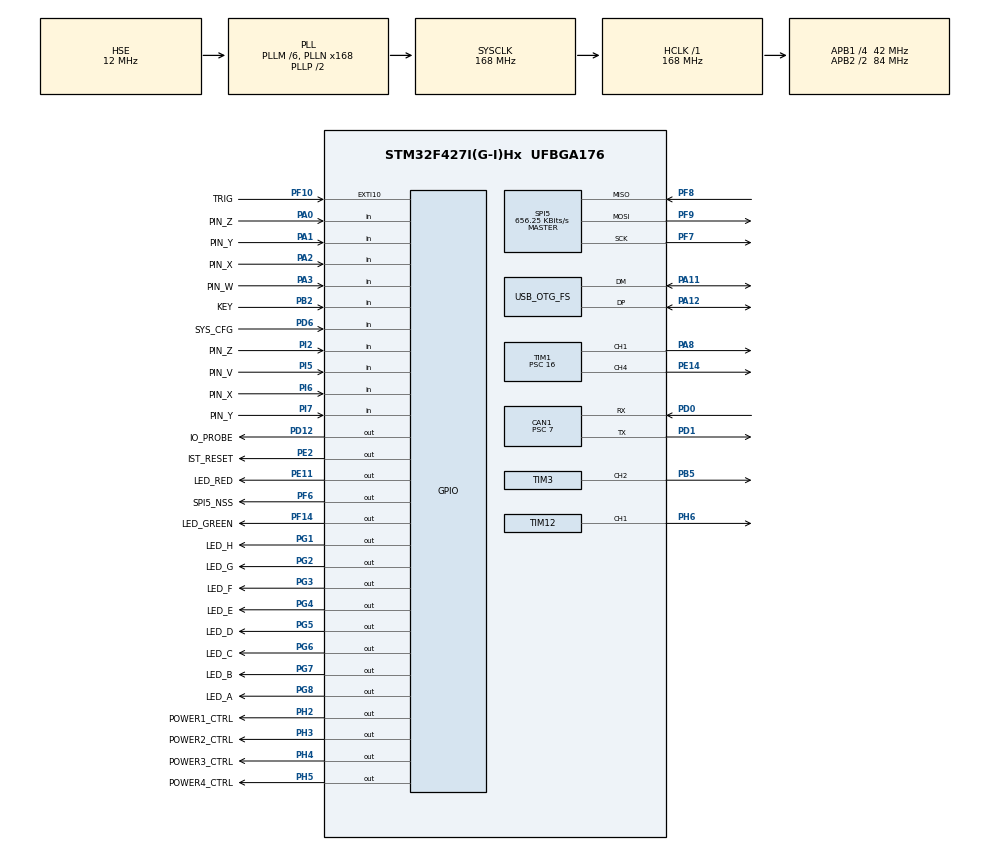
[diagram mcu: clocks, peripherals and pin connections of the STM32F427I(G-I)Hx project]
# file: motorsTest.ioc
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CAN1.BS1=CAN_BS1_2TQ
CAN1.BS2=CAN_BS2_3TQ
CAN1.CalculateBaudRate=999999
CAN1.CalculateTimeBit=1000
CAN1.CalculateTimeQuantum=166.66666666666669
CAN1.Prescaler=7
CAN1.TXFP=ENABLE
FREERTOS.INCLUDE_vTaskDelayUntil=1
FREERTOS.MEMORY_ALLOCATION=0
FREERTOS.Tasks01=defaultTask,0,128,StartDefaultTask,Default,NULL,Dynamic,NULL,NULL
FREERTOS.configCHECK_FOR_STACK_OVERFLOW=2
FREERTOS.configUSE_MALLOC_FAILED_HOOK=1
FREERTOS.configUSE_NEWLIB_REENTRANT=1
Mcu.Family=STM32F4
Mcu.Name=STM32F427I(G-I)Hx
Mcu.Package=UFBGA176
NVIC.CAN1_RX0_IRQn=true\:5\:0\:false\:false\:true\:true\:true\:true\:true
NVIC.CAN1_TX_IRQn=true\:5\:0\:false\:false\:true\:true\:true\:true\:true
NVIC.OTG_FS_IRQn=true\:5\:0\:false\:false\:true\:true\:false\:true\:true
NVIC.PriorityGroup=NVIC_PRIORITYGROUP_4
NVIC.TIM2_IRQn=true\:5\:0\:false\:false\:true\:true\:true\:true\:true
NVIC.TIM5_IRQn=true\:15\:0\:false\:false\:true\:false\:false\:true\:true
NVIC.TimeBase=TIM5_IRQn
NVIC.TimeBaseIP=TIM5
PA0/WKUP.GPIO_Label=PIN_Z
PA0/WKUP.Signal=GPIO_Input
PA1.GPIO_Label=PIN_Y
PA1.Signal=GPIO_Input
PA11.Mode=Device_Only
PA11.Signal=USB_OTG_FS_DM
PA12.Mode=Device_Only
PA12.Signal=USB_OTG_FS_DP
PA13.Mode=Serial_Wire
PA13.Signal=SYS_JTMS-SWDIO
PA14.Mode=Serial_Wire
PA14.Signal=SYS_JTCK-SWCLK
PA2.GPIO_Label=PIN_X
PA2.Signal=GPIO_Input
PA3.GPIO_Label=PIN_W
PA3.Signal=GPIO_Input
PA8.Signal=S_TIM1_CH1
PB13.Signal=CAN2_TX
PB2/BOOT1.GPIO_Label=KEY
PB2/BOOT1.Signal=GPIO_Input
PB5.Signal=S_TIM3_CH2
PD0.Mode=CAN_Activate
PD0.Signal=CAN1_RX
PD1.Mode=CAN_Activate
PD1.Signal=CAN1_TX
PD12.GPIO_Label=IO_PROBE
PD12.Signal=GPIO_Output
PD6.GPIO_Label=SYS_CFG
PD6.Signal=GPIO_Input
PD8.GPIO_PuPd=GPIO_PULLUP
PD8.Signal=USART3_TX
PD9.GPIO_PuPd=GPIO_PULLUP
PD9.Signal=USART3_RX
PE11.GPIO_Label=LED_RED
PE11.Signal=GPIO_Output
PE14.Signal=S_TIM1_CH4
PE2.GPIO_Label=IST_RESET
PE2.Signal=GPIO_Output
PF10.GPIO_Label=TRIG
PF10.GPIO_PuPd=GPIO_PULLUP
PF10.Signal=GPXTI10
PF14.GPIO_Label=LED_GREEN
PF14.Signal=GPIO_Output
PF6.GPIO_Label=SPI5_NSS
PF6.Signal=GPIO_Output
PF7.Mode=Full_Duplex_Master
PF7.Signal=SPI5_SCK
PF8.Mode=Full_Duplex_Master
PF8.Signal=SPI5_MISO
PF9.Mode=Full_Duplex_Master
PF9.Signal=SPI5_MOSI
PG1.GPIO_Label=LED_H
PG1.Signal=GPIO_Output
PG2.GPIO_Label=LED_G
PG2.Signal=GPIO_Output
PG3.GPIO_Label=LED_F
PG3.Signal=GPIO_Output
PG4.GPIO_Label=LED_E
PG4.Signal=GPIO_Output
PG5.GPIO_Label=LED_D
PG5.Signal=GPIO_Output
PG6.GPIO_Label=LED_C
PG6.Signal=GPIO_Output
PG7.GPIO_Label=LED_B
PG7.Signal=GPIO_Output
PG8.GPIO_Label=LED_A
PG8.Signal=GPIO_Output
PH0/OSC_IN.Mode=HSE-External-Oscillator
PH0/OSC_IN.Signal=RCC_OSC_IN
PH1/OSC_OUT.Mode=HSE-External-Oscillator
PH1/OSC_OUT.Signal=RCC_OSC_OUT
PH2.GPIO_Label=POWER1_CTRL
PH2.Signal=GPIO_Output
PH3.GPIO_Label=POWER2_CTRL
PH3.Signal=GPIO_Output
PH4.GPIO_Label=POWER3_CTRL
PH4.Signal=GPIO_Output
PH5.GPIO_Label=POWER4_CTRL
PH5.Signal=GPIO_Output
PH6.Signal=S_TIM12_CH1
PI2.GPIO_Label=PIN_Z
PI2.Signal=GPIO_Input
PI5.GPIO_Label=PIN_V
PI5.Signal=GPIO_Input
PI6.GPIO_Label=PIN_X
PI6.Signal=GPIO_Input
PI7.GPIO_Label=PIN_Y
PI7.Signal=GPIO_Input
ProjectManager.HeapSize=0x200
ProjectManager.StackSize=0x400
ProjectManager.TargetToolchain=STM32CubeIDE
RCC.48MHZClocksFreq_Value=48000000
RCC.AHBFreq_Value=168000000
RCC.APB1CLKDivider=RCC_HCLK_DIV4
RCC.APB1Freq_Value=42000000
RCC.APB1TimFreq_Value=84000000
RCC.APB2CLKDivider=RCC_HCLK_DIV2
RCC.APB2Freq_Value=84000000
RCC.APB2TimFreq_Value=168000000
RCC.CortexFreq_Value=168000000
RCC.HCLKFreq_Value=168000000
RCC.HSE_VALUE=12000000
RCC.HSI_VALUE=16000000
RCC.LSE_VALUE=32768
RCC.PLLM=6
RCC.PLLN=168
RCC.PLLQ=7
RCC.SYSCLKFreq_VALUE=168000000
RCC.SYSCLKSource=RCC_SYSCLKSOURCE_PLLCLK
RCC.VCOOutputFreq_Value=336000000
SH.S_TIM12_CH1.0=TIM12_CH1,PWM Generation1 CH1
SH.S_TIM1_CH1.0=TIM1_CH1,PWM Generation1 CH1
SH.S_TIM1_CH4.0=TIM1_CH4,PWM Generation4 CH4
SH.S_TIM3_CH2.0=TIM3_CH2,PWM Generation2 CH2
SPI5.BaudRatePrescaler=SPI_BAUDRATEPRESCALER_128
SPI5.CalculateBaudRate=656.25 KBits/s
SPI5.Direction=SPI_DIRECTION_2LINES
SPI5.Mode=SPI_MODE_MASTER
SPI5.VirtualType=VM_MASTER
TIM1.Channel-PWM\ Generation1\ CH1=TIM_CHANNEL_1
TIM1.Channel-PWM\ Generation4\ CH4=TIM_CHANNEL_4
TIM1.Period=20000-1
TIM1.Prescaler=16
TIM1.Pulse-PWM\ Generation1\ CH1=1000
TIM1.Pulse-PWM\ Generation4\ CH4=1000
TIM12.Channel-PWM\ Generation1\ CH1=TIM_CHANNEL_1
TIM12.Period=20000-1
TIM12.Prescaler=83
TIM2.Period=1000-1
TIM2.Prescaler=83
TIM3.Channel-PWM\ Generation2\ CH2=TIM_CHANNEL_2
TIM3.Period=2000-1
TIM3.Prescaler=83
USB_DEVICE.CLASS_NAME_FS=CDC
USB_DEVICE.VirtualMode-CDC_FS=Cdc
USB_DEVICE.VirtualModeFS=Cdc_FS
USB_OTG_FS.VirtualMode=Device_Only
VP_FREERTOS_VS_CMSIS_V1.Mode=CMSIS_V1
VP_SYS_VS_tim5.Mode=TIM5
VP_TIM2_VS_ClockSourceINT.Mode=Internal
VP_USB_DEVICE_VS_USB_DEVICE_CDC_FS.Mode=CDC_FS
board=custom

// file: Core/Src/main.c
/* USER CODE BEGIN Header */
/**
 ******************************************************************************
 * @file           : main.c
 * @brief          : Main program body
 ******************************************************************************
 * @attention
 *
 * Copyright (c) 2024 STMicroelectronics.
 * All rights reserved.
 *
 * This software is licensed under terms that can be found in the LICENSE file
 * in the root directory of this software component.
 * If no LICENSE file comes with this software, it is provided AS-IS.
 *
 ******************************************************************************
 */
/* USER CODE END Header */
#include "main.h"
#include "can.h"
#include "cmsis_os.h"
#include "gpio.h"
#include "spi.h"
#include "tim.h"
#include "usb_device.h"

/* USER CODE BEGIN Includes */
#include "init.h"
/* USER CODE END Includes */

void SystemClock_Config(void);
void MX_FREERTOS_Init(void);

int main(void) {

  /* MCU Configuration--------------------------------------------------------*/

  /* Reset of all peripherals, Initializes the Flash interface and the Systick.
   */
  HAL_Init();

  /* Configure the system clock */
  SystemClock_Config();

  /* Initialize all configured peripherals */
  MX_GPIO_Init();
  MX_SPI5_Init();
  MX_CAN1_Init();
  MX_TIM1_Init();
  MX_TIM2_Init();
  MX_TIM3_Init();
  MX_TIM12_Init();
  /* USER CODE BEGIN 2 */
  hw_init();
  init_task();
  /* USER CODE END 2 */

  /* Call init function for freertos objects (in freertos.c) */
  MX_FREERTOS_Init();

  /* Start scheduler */
  osKernelStart();

  /* We should never get here as control is now taken by the scheduler */
  /* Infinite loop */
  while (1) {

  }
}

void SystemClock_Config(void) {
  RCC_OscInitTypeDef RCC_OscInitStruct = {0};
  RCC_ClkInitTypeDef RCC_ClkInitStruct = {0};

  /** Configure the main internal regulator output voltage
   */
  __HAL_RCC_PWR_CLK_ENABLE();
  __HAL_PWR_VOLTAGESCALING_CONFIG(PWR_REGULATOR_VOLTAGE_SCALE1);

  /** Initializes the RCC Oscillators according to the specified parameters
   * in the RCC_OscInitTypeDef structure.
   */
  RCC_OscInitStruct.OscillatorType = RCC_OSCILLATORTYPE_HSE;
  RCC_OscInitStruct.HSEState = RCC_HSE_ON;
  RCC_OscInitStruct.PLL.PLLState = RCC_PLL_ON;
  RCC_OscInitStruct.PLL.PLLSource = RCC_PLLSOURCE_HSE;
  RCC_OscInitStruct.PLL.PLLM = 6;
  RCC_OscInitStruct.PLL.PLLN = 168;
  RCC_OscInitStruct.PLL.PLLP = RCC_PLLP_DIV2;
  RCC_OscInitStruct.PLL.PLLQ = 7;
  if (HAL_RCC_OscConfig(&RCC_OscInitStruct) != HAL_OK) {
    Error_Handler();
  }

  /** Initializes the CPU, AHB and APB buses clocks
   */
  RCC_ClkInitStruct.ClockType = RCC_CLOCKTYPE_HCLK | RCC_CLOCKTYPE_SYSCLK |
                                RCC_CLOCKTYPE_PCLK1 | RCC_CLOCKTYPE_PCLK2;
  RCC_ClkInitStruct.SYSCLKSource = RCC_SYSCLKSOURCE_PLLCLK;
  RCC_ClkInitStruct.AHBCLKDivider = RCC_SYSCLK_DIV1;
  RCC_ClkInitStruct.APB1CLKDivider = RCC_HCLK_DIV4;
  RCC_ClkInitStruct.APB2CLKDivider = RCC_HCLK_DIV2;

  if (HAL_RCC_ClockConfig(&RCC_ClkInitStruct, FLASH_LATENCY_5) != HAL_OK) {
    Error_Handler();
  }
}

void HAL_TIM_PeriodElapsedCallback(TIM_HandleTypeDef *htim) {
  if (htim->Instance == TIM5) {
    HAL_IncTick();
  }
}

void Error_Handler(void) {
  /* USER CODE BEGIN Error_Handler_Debug */
  /* User can add his own implementation to report the HAL error return state */
  __disable_irq();
  while (1) {
    HAL_GPIO_TogglePin(LED_A_GPIO_Port, LED_A_Pin);
    HAL_Delay(100);
  }
  /* USER CODE END Error_Handler_Debug */
}

#ifdef USE_FULL_ASSERT
/**
 * @brief  Reports the name of the source file and the source line number
 *         where the assert_param error has occurred.
 * @param  file: pointer to the source file name
 * @param  line: assert_param error line source number
 * @retval None
 */
void assert_failed(uint8_t *file, uint32_t line) {
  /* USER CODE BEGIN 6 */
  /* User can add his own implementation to report the file name and line
     number, ex: printf("Wrong parameters value: file %s on line %d\r\n", file,
     line) */
  /* USER CODE END 6 */
}
#endif /* USE_FULL_ASSERT */
